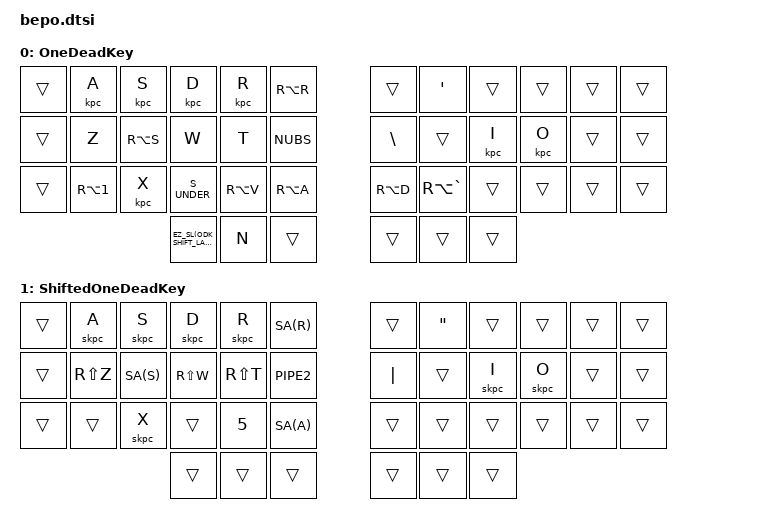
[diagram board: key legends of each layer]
#if 1
#define DK_LAYER EXTRA_LAYERS_START_INDEX
#define ODK &EZ_SL(DK_LAYER)
#else
#define ODK_LAYER        EXTRA_LAYERS_START_INDEX
#define ODK_SHIFT_LAYER (EXTRA_LAYERS_START_INDEX + 1)
#define ODK &EZ_SL(DK_LAYER) &dead_key
#endif

#define SA(key) RS(RA(key))

// Same as the default base layer, but [N] becomes 1DK.
&base_layer {
  display-name = "Base";
  bindings = <
    &kp TAB    &kp Q  &kp W  &kp E  &kp R  &kp T        &kp Y  &kp U  &kp I     &kp O   &kp P      &kp BACKSPACE
    &kp ESCAPE HRM_A  HRM_S  HRM_D  HRM_F  &kp G        &kp H  HRM_J  HRM_K     HRM_L   HRM_SEMI   &kp ENTER
    &kp LSHIFT &kp Z  &kp X  &kp C  &kp V  &kp B        ODK    &kp M  &kp COMMA &kp DOT &kp FSLH   &kp RSHIFT
            LTHUMB_TUCK  LTHUMB_HOME  LTHUMB_REACH    RTHUMB_REACH  RTHUMB_HOME  RTHUMB_TUCK
  >;
};

/ {
  behaviors {
    dead_key: dead_key {
      compatible = "zmk,behavior-mod-morph";
      #binding-cells = <0>;
      bindings = <&EZ_SL(ODK_LAYER)>, <&kp N>;
      mods      = <(MOD_LSFT|MOD_RSFT)>;
      keep-mods = <(MOD_LSFT|MOD_RSFT)>;
    };
  };

  macros {
    // tap a dead circumflex before a key
    kpc: circumflex {
      compatible = "zmk,behavior-macro-one-param";
      #binding-cells = <1>;
      tap-ms = <0>;
      wait-ms = <0>;
      bindings
        = <&macro_tap &kp Y>
        , <&macro_pause_for_release>
        , <&macro_param_1to1>
        , <&kp MACRO_PLACEHOLDER>
        ;
    };

    // tap a dead circumflex before a shifted key
    skpc: circumflex_shift {
      compatible = "zmk,behavior-macro-one-param";
      #binding-cells = <1>;
      tap-ms = <0>;
      wait-ms = <0>;
      bindings
        = <&macro_tap &kp Y>
        , <&macro_pause_for_release>
        , <&macro_press &kp LSHIFT>
        , <&macro_param_1to1>
        , <&kp MACRO_PLACEHOLDER>
        , <&macro_release &kp LSHIFT>
        ;
    };
  };

  // Extra layers defined specifically for this keymap, appended to the base keymap.
  keymap {
    compatible = "zmk,keymap";

    one_dead_key {
      display-name = "OneDeadKey";
      bindings = <
        &trans   &kpc A     &kpc S    &kpc D  &kpc R    &kp RA(R)    &trans     &kp SQT       &trans  &trans  &trans   &trans
        &trans   &kp Z      &kp RA(S) &kp W   &kp T     &kp NUBS     &kp BSLH   &trans        &kpc I  &kpc O  &trans   &trans
        &trans   &kp RA(N1) &kpc X    S_UNDER &kp RA(V) &kp RA(A)    &kp RA(D)  &kp RA(GRAVE) &trans  &trans  &trans   &trans
                           &EZ_SL(ODK_SHIFT_LAYER)  &kp N  &trans    &trans  &trans  &trans
      >;
    };

    shifted_one_dead_key {
      display-name = "ShiftedOneDeadKey";
      bindings = <
        &trans   &skpc A   &skpc S   &skpc D   &skpc R   &kp SA(R)    &trans   &kp DQT  &trans  &trans  &trans   &trans
        &trans   &kp RS(Z) &kp SA(S) &kp RS(W) &kp RS(T) &kp PIPE2    &kp PIPE &trans   &skpc I &skpc O &trans   &trans
        &trans   &trans    &skpc X   &trans    &kp N5    &kp SA(A)    &trans   &trans   &trans  &trans  &trans   &trans
                                     &trans    &trans    &trans       &trans   &trans   &trans
      >;
    };

  };
};
